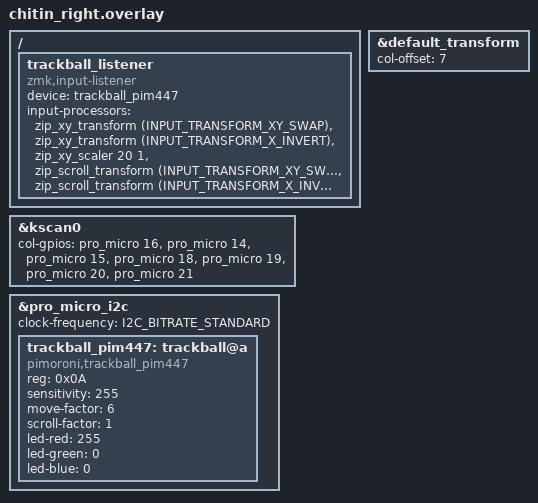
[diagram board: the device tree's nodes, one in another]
#include "chitin.dtsi"

&default_transform {
	col-offset = <7>;
};

&kscan0 {
        col-gpios 
            = <&pro_micro 16 GPIO_ACTIVE_HIGH>  // COL 13 (outer)
            , <&pro_micro 14 GPIO_ACTIVE_HIGH>  // COL 12 (pinky)
            , <&pro_micro 15 GPIO_ACTIVE_HIGH>  // COL 11 (ring)
            , <&pro_micro 18 GPIO_ACTIVE_HIGH>  // COL 10 (middle)
            , <&pro_micro 19 GPIO_ACTIVE_HIGH>  // COL 9 (index)
            , <&pro_micro 20 GPIO_ACTIVE_HIGH>  // COL 8 (inner)
            , <&pro_micro 21 GPIO_ACTIVE_HIGH>  // COL 7 (extra)
            ;
};

&pro_micro_i2c {
    status = "okay";
    clock-frequency = <I2C_BITRATE_STANDARD>;
    
    trackball_pim447: trackball@a {
        compatible = "pimoroni,trackball_pim447";
        reg = <0x0A>;

        sensitivity = <255>;  /* Range: 1-255 */
        move-factor = <6>;   /* Range: 1-10, scales cursor movement speed */
        scroll-factor = <1>; /* Range: 1-10, scales scrolling speed */
        
        /* Optional LED color (RGB values 0-255) */
        led-red = <255>;
        led-green = <0>;
        led-blue = <0>;
        
        /* Optional axis inversion */
        /* invert-x; */   /* Uncomment to invert X axis */
        /* invert-y; */   /* Uncomment to invert Y axis */
    };
};

/ {
    trackball_listener {
        compatible = "zmk,input-listener";
        device = <&trackball_pim447>;
        status = "okay";

        input-processors = <
            &zip_xy_transform (INPUT_TRANSFORM_XY_SWAP)
            &zip_xy_transform (INPUT_TRANSFORM_X_INVERT)

            &zip_xy_scaler 20 1

            &zip_scroll_transform (INPUT_TRANSFORM_XY_SWAP)
            &zip_scroll_transform (INPUT_TRANSFORM_X_INVERT)
        >;
    };
};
